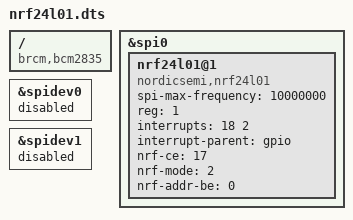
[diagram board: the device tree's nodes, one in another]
/dts-v1/;
/plugin/;

/ {
        compatible = "brcm,bcm2835", "brcm,bcm2708", "brcm,bcm2709";

        fragment@0 {
                target = <&spi0>;
                __overlay__ {
                        status = "okay";
                };
        };

        fragment@1 {
                target = <&spidev0>;
                __overlay__ {
                        status = "disabled";                   
                };
        };

        fragment@2 {
                target = <&spidev1>;
                __overlay__ {
                        status = "disabled";                   
                };
        };

        fragment@3 {
                target = <&spi0>;
                __overlay__ {
                        #address-cells = <1>;
                        #size-cells = <0>;

                        nrf24l01@1 {
                                status = "okay";
                                compatible = "nordicsemi,nrf24l01";
                                spi-max-frequency = <10000000>;
                                reg = <1>;
                                interrupts = <18 2>;
                                interrupt-parent = <&gpio>;
                                nrf-ce = <17>;
                                nrf-mode = <2>;
                                nrf-addr-be = <0>;
                        };

                };
        };
};
